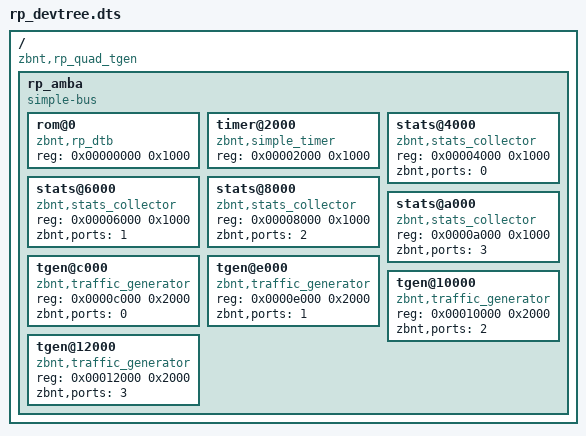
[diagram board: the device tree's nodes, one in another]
/*
	This Source Code Form is subject to the terms of the Mozilla Public
	License, v. 2.0. If a copy of the MPL was not distributed with this
	file, You can obtain one at https://mozilla.org/MPL/2.0/.
*/

/dts-v1/;

/ {
	#address-cells = <1>;
	#size-cells = <1>;
	compatible = "zbnt,rp_quad_tgen";

	rp_amba {
		compatible = "simple-bus";
		#address-cells = <1>;
		#size-cells = <1>;

		rom@0 {
			compatible = "zbnt,rp_dtb";
			reg = <0x00000000 0x1000>;
		};

		timer@2000 {
			compatible = "zbnt,simple_timer";
			reg = <0x00002000 0x1000>;
		};

		stats@4000 {
			compatible = "zbnt,stats_collector";
			reg = <0x00004000 0x1000>;
			zbnt,ports = <0>;
		};

		stats@6000 {
			compatible = "zbnt,stats_collector";
			reg = <0x00006000 0x1000>;
			zbnt,ports = <1>;
		};

		stats@8000 {
			compatible = "zbnt,stats_collector";
			reg = <0x00008000 0x1000>;
			zbnt,ports = <2>;
		};

		stats@a000 {
			compatible = "zbnt,stats_collector";
			reg = <0x0000a000 0x1000>;
			zbnt,ports = <3>;
		};

		tgen@c000 {
			compatible = "zbnt,traffic_generator";
			reg = <0x0000c000 0x2000>;
			zbnt,ports = <0>;
		};

		tgen@e000 {
			compatible = "zbnt,traffic_generator";
			reg = <0x0000e000 0x2000>;
			zbnt,ports = <1>;
		};

		tgen@10000 {
			compatible = "zbnt,traffic_generator";
			reg = <0x00010000 0x2000>;
			zbnt,ports = <2>;
		};

		tgen@12000 {
			compatible = "zbnt,traffic_generator";
			reg = <0x00012000 0x2000>;
			zbnt,ports = <3>;
		};
	};
};
